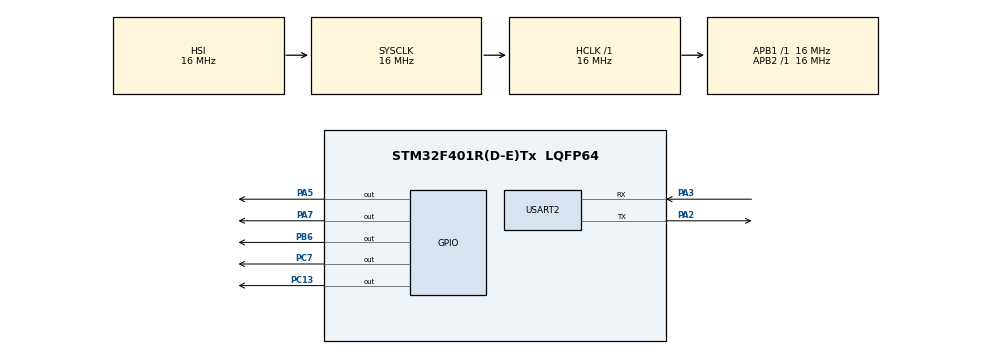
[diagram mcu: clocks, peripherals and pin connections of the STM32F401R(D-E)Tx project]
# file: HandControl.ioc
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Mcu.Family=STM32F4
RCC.CortexFreq_Value=16000000
PC13-ANTI_TAMP.GPIO_PuPd=GPIO_PULLDOWN
PB6.GPIO_PuPd=GPIO_PULLDOWN
PH1\ -\ OSC_OUT.Mode=HSE-External-Oscillator
NVIC.USART2_IRQn=true\:0\:0\:false\:false\:true\:true\:true
ProjectManager.StackSize=0x400
PA13.Signal=SYS_JTMS-SWDIO
PA3.Mode=Asynchronous
PH0\ -\ OSC_IN.Mode=HSE-External-Oscillator
PH0\ -\ OSC_IN.Signal=RCC_OSC_IN
ProjectManager.TargetToolchain=STM32CubeIDE
RCC.HCLKFreq_Value=16000000
RCC.APB2TimFreq_Value=16000000
PB6.Signal=GPIO_Output
PC7.Signal=GPIO_Output
PC7.GPIO_PuPd=GPIO_PULLDOWN
RCC.LSE_VALUE=32768
PA7.GPIO_PuPd=GPIO_PULLDOWN
RCC.AHBFreq_Value=16000000
PA5.Signal=GPIO_Output
RCC.HSE_VALUE=25000000
PH1\ -\ OSC_OUT.Signal=RCC_OSC_OUT
board=custom
PC13-ANTI_TAMP.Signal=GPIO_Output
RCC.VCOOutputFreq_Value=192000000
RCC.APB2Freq_Value=16000000
PA14.Mode=Serial_Wire
PA5.GPIO_PuPd=GPIO_PULLDOWN
PA13.Mode=Serial_Wire
Mcu.Name=STM32F401R(D-E)Tx
PA2.Signal=USART2_TX
RCC.SYSCLKFreq_VALUE=16000000
Mcu.Package=LQFP64
USART2.VirtualMode=VM_ASYNC
PA14.Signal=SYS_JTCK-SWCLK
ProjectManager.HeapSize=0x200
RCC.HSI_VALUE=16000000
NVIC.PriorityGroup=NVIC_PRIORITYGROUP_4
RCC.APB1TimFreq_Value=16000000
PA2.Mode=Asynchronous
RCC.APB1Freq_Value=16000000
NVIC.RCC_IRQn=true\:0\:0\:false\:false\:true\:true\:false
PA3.Signal=USART2_RX
PA7.Signal=GPIO_Output

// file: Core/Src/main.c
/* USER CODE BEGIN Header */
/**
  ******************************************************************************
  * @file           : main.c
  * @brief          : Main program body
  ******************************************************************************
  * @attention
  *
  * <h2><center>&copy; Copyright (c) 2021 STMicroelectronics.
  * All rights reserved.</center></h2>
  *
  * This software component is licensed by ST under BSD 3-Clause license,
  * the "License"; You may not use this file except in compliance with the
  * License. You may obtain a copy of the License at:
  *                        opensource.org/licenses/BSD-3-Clause
  *
  ******************************************************************************
  */
/* USER CODE END Header */
#include "main.h"

UART_HandleTypeDef huart2;

void SystemClock_Config(void);
static void MX_GPIO_Init(void);
static void MX_USART2_UART_Init(void);

int main(void)
{

  /* MCU Configuration--------------------------------------------------------*/

  /* Reset of all peripherals, Initializes the Flash interface and the Systick. */
  HAL_Init();

  /* Configure the system clock */
  SystemClock_Config();

  /* Initialize all configured peripherals */
  MX_GPIO_Init();
  MX_USART2_UART_Init();
  /* USER CODE BEGIN 2 */
  uint8_t Data;
  /* USER CODE END 2 */

  /* Infinite loop */
  /* USER CODE BEGIN WHILE */
  while (1)
  {

	  HAL_UART_Receive(&huart2, &Data, 1, 500);
	  if(Data == 0){
		  HAL_GPIO_WritePin(GPIOA, GPIO_PIN_7, RESET );	//IN2
		  HAL_GPIO_WritePin(GPIOC, GPIO_PIN_7, RESET ); //ENA
		  HAL_GPIO_WritePin(GPIOB, GPIO_PIN_6, RESET ); //IN1
	  }
	  else if(Data == 1){
//		  HAL_GPIO_WritePin(GPIOA, GPIO_PIN_5, SET );
		  HAL_GPIO_WritePin(GPIOA, GPIO_PIN_7, SET );	//IN2
		  HAL_GPIO_WritePin(GPIOC, GPIO_PIN_7, SET ); //ENA
		  HAL_GPIO_WritePin(GPIOB, GPIO_PIN_6, RESET ); //IN1
	  }

		  else{
			  HAL_GPIO_WritePin(GPIOA, GPIO_PIN_7, RESET );	//IN2
			  HAL_GPIO_WritePin(GPIOC, GPIO_PIN_7, SET ); //ENA
			  HAL_GPIO_WritePin(GPIOB, GPIO_PIN_6, SET ); //IN1
		  }

	  //HAL_UART_Transmit(&huart2, &Data, 1, 1000);
	  //HAL_Delay(2);
    /* USER CODE END WHILE */

  }
}

void SystemClock_Config(void)
{
  RCC_OscInitTypeDef RCC_OscInitStruct = {0};
  RCC_ClkInitTypeDef RCC_ClkInitStruct = {0};

  /** Configure the main internal regulator output voltage
  */
  __HAL_RCC_PWR_CLK_ENABLE();
  __HAL_PWR_VOLTAGESCALING_CONFIG(PWR_REGULATOR_VOLTAGE_SCALE2);
  /** Initializes the RCC Oscillators according to the specified parameters
  * in the RCC_OscInitTypeDef structure.
  */
  RCC_OscInitStruct.OscillatorType = RCC_OSCILLATORTYPE_HSI;
  RCC_OscInitStruct.HSIState = RCC_HSI_ON;
  RCC_OscInitStruct.HSICalibrationValue = RCC_HSICALIBRATION_DEFAULT;
  RCC_OscInitStruct.PLL.PLLState = RCC_PLL_NONE;
  if (HAL_RCC_OscConfig(&RCC_OscInitStruct) != HAL_OK)
  {
    Error_Handler();
  }
  /** Initializes the CPU, AHB and APB buses clocks
  */
  RCC_ClkInitStruct.ClockType = RCC_CLOCKTYPE_HCLK|RCC_CLOCKTYPE_SYSCLK
                              |RCC_CLOCKTYPE_PCLK1|RCC_CLOCKTYPE_PCLK2;
  RCC_ClkInitStruct.SYSCLKSource = RCC_SYSCLKSOURCE_HSI;
  RCC_ClkInitStruct.AHBCLKDivider = RCC_SYSCLK_DIV1;
  RCC_ClkInitStruct.APB1CLKDivider = RCC_HCLK_DIV1;
  RCC_ClkInitStruct.APB2CLKDivider = RCC_HCLK_DIV1;

  if (HAL_RCC_ClockConfig(&RCC_ClkInitStruct, FLASH_LATENCY_0) != HAL_OK)
  {
    Error_Handler();
  }
}

static void MX_USART2_UART_Init(void)
{

  huart2.Instance = USART2;
  huart2.Init.BaudRate = 115200;
  huart2.Init.WordLength = UART_WORDLENGTH_8B;
  huart2.Init.StopBits = UART_STOPBITS_1;
  huart2.Init.Parity = UART_PARITY_NONE;
  huart2.Init.Mode = UART_MODE_TX_RX;
  huart2.Init.HwFlowCtl = UART_HWCONTROL_NONE;
  huart2.Init.OverSampling = UART_OVERSAMPLING_16;
  if (HAL_UART_Init(&huart2) != HAL_OK)
  {
    Error_Handler();
  }

}

static void MX_GPIO_Init(void)
{
  GPIO_InitTypeDef GPIO_InitStruct = {0};

  /* GPIO Ports Clock Enable */
  __HAL_RCC_GPIOC_CLK_ENABLE();
  __HAL_RCC_GPIOH_CLK_ENABLE();
  __HAL_RCC_GPIOA_CLK_ENABLE();
  __HAL_RCC_GPIOB_CLK_ENABLE();

  /*Configure GPIO pin Output Level */
  HAL_GPIO_WritePin(GPIOC, GPIO_PIN_13|GPIO_PIN_7, GPIO_PIN_RESET);

  /*Configure GPIO pin Output Level */
  HAL_GPIO_WritePin(GPIOA, GPIO_PIN_5|GPIO_PIN_7, GPIO_PIN_RESET);

  /*Configure GPIO pin Output Level */
  HAL_GPIO_WritePin(GPIOB, GPIO_PIN_6, GPIO_PIN_RESET);

  /*Configure GPIO pins : PC13 PC7 */
  GPIO_InitStruct.Pin = GPIO_PIN_13|GPIO_PIN_7;
  GPIO_InitStruct.Mode = GPIO_MODE_OUTPUT_PP;
  GPIO_InitStruct.Pull = GPIO_PULLDOWN;
  GPIO_InitStruct.Speed = GPIO_SPEED_FREQ_LOW;
  HAL_GPIO_Init(GPIOC, &GPIO_InitStruct);

  /*Configure GPIO pins : PA5 PA7 */
  GPIO_InitStruct.Pin = GPIO_PIN_5|GPIO_PIN_7;
  GPIO_InitStruct.Mode = GPIO_MODE_OUTPUT_PP;
  GPIO_InitStruct.Pull = GPIO_PULLDOWN;
  GPIO_InitStruct.Speed = GPIO_SPEED_FREQ_LOW;
  HAL_GPIO_Init(GPIOA, &GPIO_InitStruct);

  /*Configure GPIO pin : PB6 */
  GPIO_InitStruct.Pin = GPIO_PIN_6;
  GPIO_InitStruct.Mode = GPIO_MODE_OUTPUT_PP;
  GPIO_InitStruct.Pull = GPIO_PULLDOWN;
  GPIO_InitStruct.Speed = GPIO_SPEED_FREQ_LOW;
  HAL_GPIO_Init(GPIOB, &GPIO_InitStruct);

}

void Error_Handler(void)
{
  __disable_irq();
  while (1)
  {
  }
}

/************************ (C) COPYRIGHT STMicroelectronics *****END OF FILE****/
